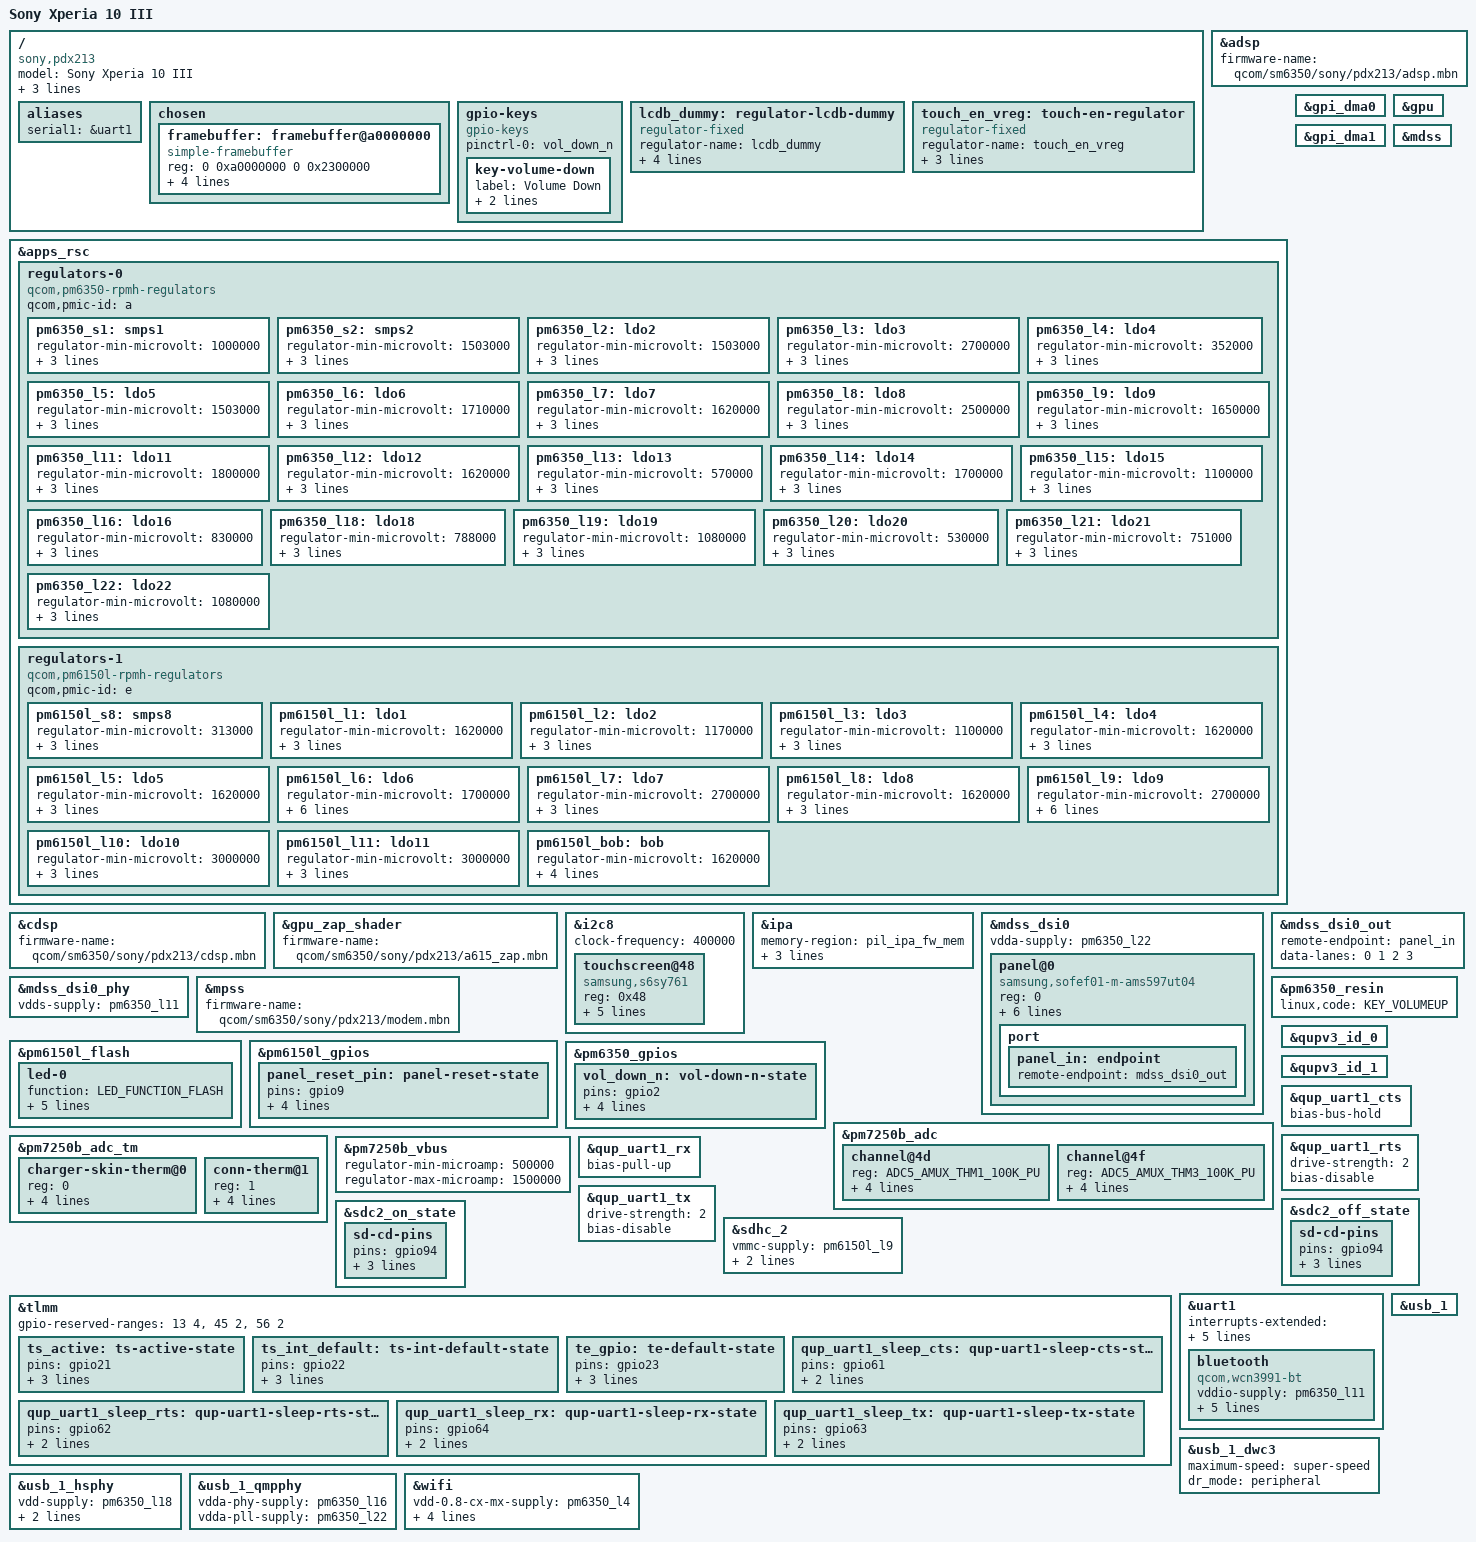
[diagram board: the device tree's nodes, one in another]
// SPDX-License-Identifier: BSD-3-Clause
/*
 * Copyright (c) 2021, Konrad Dybcio <konrad.dybcio@somainline.org>
 */
/dts-v1/;

/* PM7250B is configured to use SID2/3 */
#define PM7250B_SID 2
#define PM7250B_SID1 3

#include <dt-bindings/leds/common.h>
#include <dt-bindings/pinctrl/qcom,pmic-gpio.h>
#include <dt-bindings/regulator/qcom,rpmh-regulator.h>
#include "sm6350.dtsi"
#include "pm6150l.dtsi"
#include "pm6350.dtsi"
#include "pm7250b.dtsi"

/ {
	model = "Sony Xperia 10 III";
	compatible = "sony,pdx213", "qcom,sm6350";
	chassis-type = "handset";
	qcom,msm-id = <434 0x10000>, <459 0x10000>;
	qcom,board-id = <0x1000b 0>;

	aliases {
		serial1 = &uart1;
	};

	chosen {
		#address-cells = <2>;
		#size-cells = <2>;
		ranges;

		framebuffer: framebuffer@a0000000 {
			compatible = "simple-framebuffer";
			reg = <0 0xa0000000 0 0x2300000>;
			width = <1080>;
			height = <2520>;
			stride = <(1080 * 4)>;
			format = "a8r8g8b8";
		};
	};

	gpio-keys {
		compatible = "gpio-keys";
		pinctrl-names = "default";
		pinctrl-0 = <&vol_down_n>;

		key-volume-down {
			label = "Volume Down";
			linux,code = <KEY_VOLUMEDOWN>;
			gpios = <&pm6350_gpios 2 GPIO_ACTIVE_LOW>;
		};
	};

	lcdb_dummy: regulator-lcdb-dummy {
		compatible = "regulator-fixed";
		regulator-name = "lcdb_dummy";
		regulator-min-microvolt = <5500000>;
		regulator-max-microvolt = <5500000>;
		regulator-always-on;
		regulator-boot-on;
	};

	touch_en_vreg: touch-en-regulator {
		compatible = "regulator-fixed";
		regulator-name = "touch_en_vreg";
		gpio = <&tlmm 10 GPIO_ACTIVE_HIGH>;
		enable-active-high;

		vin-supply = <&pm6350_l6>;
	};
};

&adsp {
	firmware-name = "qcom/sm6350/sony/pdx213/adsp.mbn";

	status = "okay";
};

&apps_rsc {
	regulators-0 {
		compatible = "qcom,pm6350-rpmh-regulators";
		qcom,pmic-id = "a";

		pm6350_s1: smps1 {
			regulator-min-microvolt = <1000000>;
			regulator-max-microvolt = <1200000>;
			regulator-initial-mode = <RPMH_REGULATOR_MODE_HPM>;
		};

		pm6350_s2: smps2 {
			regulator-min-microvolt = <1503000>;
			regulator-max-microvolt = <2048000>;
			regulator-initial-mode = <RPMH_REGULATOR_MODE_HPM>;
		};

		pm6350_l2: ldo2 {
			regulator-min-microvolt = <1503000>;
			regulator-max-microvolt = <1980000>;
			regulator-initial-mode = <RPMH_REGULATOR_MODE_HPM>;
		};

		pm6350_l3: ldo3 {
			regulator-min-microvolt = <2700000>;
			regulator-max-microvolt = <3300000>;
			regulator-initial-mode = <RPMH_REGULATOR_MODE_HPM>;
		};

		pm6350_l4: ldo4 {
			regulator-min-microvolt = <352000>;
			regulator-max-microvolt = <801000>;
			regulator-initial-mode = <RPMH_REGULATOR_MODE_HPM>;
		};

		pm6350_l5: ldo5 {
			regulator-min-microvolt = <1503000>;
			regulator-max-microvolt = <1980000>;
			regulator-initial-mode = <RPMH_REGULATOR_MODE_HPM>;
		};

		pm6350_l6: ldo6 {
			regulator-min-microvolt = <1710000>;
			regulator-max-microvolt = <3544000>;
			regulator-initial-mode = <RPMH_REGULATOR_MODE_HPM>;
		};

		pm6350_l7: ldo7 {
			regulator-min-microvolt = <1620000>;
			regulator-max-microvolt = <1980000>;
			regulator-initial-mode = <RPMH_REGULATOR_MODE_HPM>;
		};

		pm6350_l8: ldo8 {
			regulator-min-microvolt = <2500000>;
			regulator-max-microvolt = <3544000>;
			regulator-initial-mode = <RPMH_REGULATOR_MODE_HPM>;
		};

		pm6350_l9: ldo9 {
			regulator-min-microvolt = <1650000>;
			regulator-max-microvolt = <3401000>;
			regulator-initial-mode = <RPMH_REGULATOR_MODE_HPM>;
		};

		pm6350_l11: ldo11 {
			regulator-min-microvolt = <1800000>;
			regulator-max-microvolt = <2000000>;
			regulator-initial-mode = <RPMH_REGULATOR_MODE_HPM>;
		};

		pm6350_l12: ldo12 {
			regulator-min-microvolt = <1620000>;
			regulator-max-microvolt = <1980000>;
			regulator-initial-mode = <RPMH_REGULATOR_MODE_HPM>;
		};

		pm6350_l13: ldo13 {
			regulator-min-microvolt = <570000>;
			regulator-max-microvolt = <650000>;
			regulator-initial-mode = <RPMH_REGULATOR_MODE_HPM>;
		};

		pm6350_l14: ldo14 {
			regulator-min-microvolt = <1700000>;
			regulator-max-microvolt = <1900000>;
			regulator-initial-mode = <RPMH_REGULATOR_MODE_HPM>;
		};

		pm6350_l15: ldo15 {
			regulator-min-microvolt = <1100000>;
			regulator-max-microvolt = <1305000>;
			regulator-initial-mode = <RPMH_REGULATOR_MODE_HPM>;
		};

		pm6350_l16: ldo16 {
			regulator-min-microvolt = <830000>;
			regulator-max-microvolt = <921000>;
			regulator-initial-mode = <RPMH_REGULATOR_MODE_HPM>;
		};

		pm6350_l18: ldo18 {
			regulator-min-microvolt = <788000>;
			regulator-max-microvolt = <1049000>;
			regulator-initial-mode = <RPMH_REGULATOR_MODE_HPM>;
		};

		pm6350_l19: ldo19 {
			regulator-min-microvolt = <1080000>;
			regulator-max-microvolt = <1305000>;
			regulator-initial-mode = <RPMH_REGULATOR_MODE_HPM>;
		};

		pm6350_l20: ldo20 {
			regulator-min-microvolt = <530000>;
			regulator-max-microvolt = <801000>;
			regulator-initial-mode = <RPMH_REGULATOR_MODE_HPM>;
		};

		pm6350_l21: ldo21 {
			regulator-min-microvolt = <751000>;
			regulator-max-microvolt = <825000>;
			regulator-initial-mode = <RPMH_REGULATOR_MODE_HPM>;
		};

		pm6350_l22: ldo22 {
			regulator-min-microvolt = <1080000>;
			regulator-max-microvolt = <1305000>;
			regulator-initial-mode = <RPMH_REGULATOR_MODE_HPM>;
		};
	};

	regulators-1 {
		compatible = "qcom,pm6150l-rpmh-regulators";
		qcom,pmic-id = "e";

		pm6150l_s8: smps8 {
			regulator-min-microvolt = <313000>;
			regulator-max-microvolt = <1395000>;
			regulator-initial-mode = <RPMH_REGULATOR_MODE_HPM>;
		};

		pm6150l_l1: ldo1 {
			regulator-min-microvolt = <1620000>;
			regulator-max-microvolt = <1980000>;
			regulator-initial-mode = <RPMH_REGULATOR_MODE_HPM>;
		};

		pm6150l_l2: ldo2 {
			regulator-min-microvolt = <1170000>;
			regulator-max-microvolt = <1305000>;
			regulator-initial-mode = <RPMH_REGULATOR_MODE_HPM>;
		};

		pm6150l_l3: ldo3 {
			regulator-min-microvolt = <1100000>;
			regulator-max-microvolt = <1299000>;
			regulator-initial-mode = <RPMH_REGULATOR_MODE_HPM>;
		};

		pm6150l_l4: ldo4 {
			regulator-min-microvolt = <1620000>;
			regulator-max-microvolt = <3300000>;
			regulator-initial-mode = <RPMH_REGULATOR_MODE_HPM>;
		};

		pm6150l_l5: ldo5 {
			regulator-min-microvolt = <1620000>;
			regulator-max-microvolt = <3300000>;
			regulator-initial-mode = <RPMH_REGULATOR_MODE_HPM>;
		};

		pm6150l_l6: ldo6 {
			regulator-min-microvolt = <1700000>;
			regulator-max-microvolt = <2950000>;
			regulator-initial-mode = <RPMH_REGULATOR_MODE_HPM>;
			regulator-allow-set-load;
			regulator-allowed-modes = <RPMH_REGULATOR_MODE_LPM
						   RPMH_REGULATOR_MODE_HPM>;
		};

		pm6150l_l7: ldo7 {
			regulator-min-microvolt = <2700000>;
			regulator-max-microvolt = <3544000>;
			regulator-initial-mode = <RPMH_REGULATOR_MODE_HPM>;
		};

		pm6150l_l8: ldo8 {
			regulator-min-microvolt = <1620000>;
			regulator-max-microvolt = <2000000>;
			regulator-initial-mode = <RPMH_REGULATOR_MODE_HPM>;
		};

		pm6150l_l9: ldo9 {
			regulator-min-microvolt = <2700000>;
			regulator-max-microvolt = <2960000>;
			regulator-initial-mode = <RPMH_REGULATOR_MODE_HPM>;
			regulator-allow-set-load;
			regulator-allowed-modes = <RPMH_REGULATOR_MODE_LPM
						   RPMH_REGULATOR_MODE_HPM>;
		};

		pm6150l_l10: ldo10 {
			regulator-min-microvolt = <3000000>;
			regulator-max-microvolt = <3401000>;
			regulator-initial-mode = <RPMH_REGULATOR_MODE_HPM>;
		};

		pm6150l_l11: ldo11 {
			regulator-min-microvolt = <3000000>;
			regulator-max-microvolt = <3401000>;
			regulator-initial-mode = <RPMH_REGULATOR_MODE_HPM>;
		};

		pm6150l_bob: bob {
			regulator-min-microvolt = <1620000>;
			regulator-max-microvolt = <5492000>;
			regulator-initial-mode = <RPMH_REGULATOR_MODE_AUTO>;
			regulator-allow-bypass;
		};
	};
};

&cdsp {
	firmware-name = "qcom/sm6350/sony/pdx213/cdsp.mbn";

	status = "okay";
};

&gpi_dma0 {
	status = "okay";
};

&gpi_dma1 {
	status = "okay";
};

&gpu {
	status = "okay";
};

&gpu_zap_shader {
	firmware-name = "qcom/sm6350/sony/pdx213/a615_zap.mbn";
};

&i2c8 {
	clock-frequency = <400000>;
	status = "okay";

	touchscreen@48 {
		compatible = "samsung,s6sy761";
		reg = <0x48>;
		interrupt-parent = <&tlmm>;
		interrupts = <22 IRQ_TYPE_LEVEL_LOW>;
		vdd-supply = <&pm6350_l11>;
		avdd-supply = <&touch_en_vreg>;

		pinctrl-names = "default";
		pinctrl-0 = <&ts_int_default &ts_active>;
	};
};

&ipa {
	memory-region = <&pil_ipa_fw_mem>;
	firmware-name = "qcom/sm6350/sony/pdx213/ipa_fws.mbn";
	qcom,gsi-loader = "self";

	status = "okay";
};

&mdss {
	status = "okay";
};

&mdss_dsi0 {
	vdda-supply = <&pm6350_l22>;

	status = "okay";

	panel@0 {
		compatible = "samsung,sofef01-m-ams597ut04";
		reg = <0>;

		reset-gpios = <&pm6150l_gpios 9 GPIO_ACTIVE_LOW>;

		vci-supply = <&pm6350_l6>;
		vddio-supply = <&pm6350_l11>;
		vsn-supply = <&lcdb_dummy>;
		vsp-supply = <&lcdb_dummy>;

		pinctrl-0 = <&te_gpio &panel_reset_pin>;
		pinctrl-names = "default";

		port {
			panel_in: endpoint {
				remote-endpoint = <&mdss_dsi0_out>;
			};
		};
	};
};

&mdss_dsi0_out {
	remote-endpoint = <&panel_in>;
	data-lanes = <0 1 2 3>;
};

&mdss_dsi0_phy {
	vdds-supply = <&pm6350_l11>;

	status = "okay";
};

&mpss {
	firmware-name = "qcom/sm6350/sony/pdx213/modem.mbn";

	status = "okay";
};

&pm6150l_flash {
	status = "okay";

	led-0 {
		function = LED_FUNCTION_FLASH;
		color = <LED_COLOR_ID_WHITE>; // guess
		led-sources = <1>;
		led-max-microamp = <180000>;
		flash-max-microamp = <1000000>;
		flash-max-timeout-us = <1280000>;
	};
};

&pm6150l_gpios {
	panel_reset_pin: panel-reset-state {
		pins = "gpio9";
		function = "func1";
		power-source = <1>;
		bias-disable;
		output-low;
	};
};

&pm6350_gpios {
	vol_down_n: vol-down-n-state {
		pins = "gpio2";
		function = PMIC_GPIO_FUNC_NORMAL;
		power-source = <0>;
		bias-disable;
		input-enable;
	};
};

&pm6350_resin {
	linux,code = <KEY_VOLUMEUP>;
	status = "okay";
};

&pm7250b_adc {
	channel@4d {
		reg = <ADC5_AMUX_THM1_100K_PU>;
		qcom,ratiometric;
		qcom,hw-settle-time = <200>;
		qcom,pre-scaling = <1 1>;
		label = "charger_skin_therm";
	};

	channel@4f {
		reg = <ADC5_AMUX_THM3_100K_PU>;
		qcom,ratiometric;
		qcom,hw-settle-time = <200>;
		qcom,pre-scaling = <1 1>;
		label = "conn_therm";
	};
};

&pm7250b_adc_tm {
	status = "okay";

	charger-skin-therm@0 {
		reg = <0>;
		io-channels = <&pm7250b_adc ADC5_AMUX_THM1_100K_PU>;
		qcom,ratiometric;
		qcom,hw-settle-time-us = <200>;
	};

	conn-therm@1 {
		reg = <1>;
		io-channels = <&pm7250b_adc ADC5_AMUX_THM3_100K_PU>;
		qcom,ratiometric;
		qcom,hw-settle-time-us = <200>;
	};
};

&pm7250b_vbus {
	regulator-min-microamp = <500000>;
	regulator-max-microamp = <1500000>;

	status = "okay";
};

&qupv3_id_0 {
	status = "okay";
};

&qupv3_id_1 {
	status = "okay";
};

/* UART1: HS UART for Bluetooth */
&qup_uart1_cts {
	/*
	 * Configure a bias-bus-hold on CTS to lower power
	 * usage when Bluetooth is turned off. Bus hold will
	 * maintain a low power state regardless of whether
	 * the Bluetooth module drives the pin in either
	 * direction or leaves the pin fully unpowered.
	 */
	bias-bus-hold;
};

&qup_uart1_rts {
	/* We'll drive RTS, so no pull */
	drive-strength = <2>;
	bias-disable;
};

&qup_uart1_rx {
	/*
	 * Configure a pull-up on RX. This is needed to avoid
	 * garbage data when the TX pin of the Bluetooth module is
	 * in tri-state (module powered off or not driving the
	 * signal yet).
	 */
	bias-pull-up;
};

&qup_uart1_tx {
	/* We'll drive TX, so no pull */
	drive-strength = <2>;
	bias-disable;
};

&sdc2_off_state {
	sd-cd-pins {
		pins = "gpio94";
		function = "gpio";
		drive-strength = <2>;
		bias-disable;
	};
};

&sdc2_on_state {
	sd-cd-pins {
		pins = "gpio94";
		function = "gpio";
		drive-strength = <2>;
		bias-pull-up;
	};
};

&sdhc_2 {
	status = "okay";

	vmmc-supply = <&pm6150l_l9>;
	vqmmc-supply = <&pm6150l_l6>;

	cd-gpios = <&tlmm 94 GPIO_ACTIVE_HIGH>;
};

&tlmm {
	gpio-reserved-ranges = <13 4>, <45 2>, <56 2>;

	ts_active: ts-active-state {
		pins = "gpio21";
		function = "gpio";
		drive-strength = <8>;
		bias-pull-up;
	};

	ts_int_default: ts-int-default-state {
		pins = "gpio22";
		function = "gpio";
		drive-strength = <2>;
		bias-disable;
	};

	te_gpio: te-default-state {
		pins = "gpio23";
		function = "mdp_vsync";
		drive-strength = <2>;
		bias-pull-down;
	};

	qup_uart1_sleep_cts: qup-uart1-sleep-cts-state {
		pins = "gpio61";
		function = "gpio";
		/*
		 * Configure a bias-bus-hold on CTS to lower power
		 * usage when Bluetooth is turned off. Bus hold will
		 * maintain a low power state regardless of whether
		 * the Bluetooth module drives the pin in either
		 * direction or leaves the pin fully unpowered.
		 */
		bias-bus-hold;
	};

	qup_uart1_sleep_rts: qup-uart1-sleep-rts-state {
		pins = "gpio62";
		function = "gpio";
		/*
		 * Configure pull-down on RTS. As RTS is active low
		 * signal, pull it low to indicate the BT SoC that it
		 * can wakeup the system anytime from suspend state by
		 * pulling RX low (by sending wakeup bytes).
		 */
		bias-pull-down;
	};

	qup_uart1_sleep_rx: qup-uart1-sleep-rx-state {
		pins = "gpio64";
		function = "gpio";
		/*
		 * Configure a pull-up on RX. This is needed to avoid
		 * garbage data when the TX pin of the Bluetooth module
		 * is floating which may cause spurious wakeups.
		 */
		bias-pull-up;
	};

	qup_uart1_sleep_tx: qup-uart1-sleep-tx-state {
		pins = "gpio63";
		function = "gpio";
		/*
		 * Configure pull-up on TX when it isn't actively driven
		 * to prevent BT SoC from receiving garbage during sleep.
		 */
		bias-pull-up;
	};
};

&uart1 {
	/delete-property/ interrupts;
	interrupts-extended = <&intc GIC_SPI 602 IRQ_TYPE_LEVEL_HIGH>,
			     <&tlmm 64 IRQ_TYPE_EDGE_FALLING>;

	pinctrl-names = "default", "sleep";
	pinctrl-1 = <&qup_uart1_sleep_cts>, <&qup_uart1_sleep_rts>, <&qup_uart1_sleep_tx>, <&qup_uart1_sleep_rx>;

	status = "okay";

	bluetooth {
		compatible = "qcom,wcn3991-bt";
		vddio-supply = <&pm6350_l11>;
		vddxo-supply = <&pm6350_l7>;
		vddrf-supply = <&pm6150l_l2>;
		vddch0-supply = <&pm6150l_l10>;
		swctrl-gpios = <&tlmm 69 GPIO_ACTIVE_HIGH>;
		firmware-name = "crnv32u.bin";
	};
};

&usb_1 {
	status = "okay";
};

&usb_1_dwc3 {
	/delete-property/ usb-role-switch;
	maximum-speed = "super-speed";
	dr_mode = "peripheral";
};

&usb_1_hsphy {
	vdd-supply = <&pm6350_l18>;
	vdda-phy-dpdm-supply = <&pm6350_l3>;
	vdda-pll-supply = <&pm6350_l2>;

	status = "okay";
};

&usb_1_qmpphy {
	vdda-phy-supply = <&pm6350_l16>;
	vdda-pll-supply = <&pm6350_l22>;

	status = "okay";
};

&wifi {
	vdd-0.8-cx-mx-supply = <&pm6350_l4>;
	vdd-1.8-xo-supply = <&pm6350_l7>;
	vdd-1.3-rfa-supply = <&pm6150l_l2>;
	vdd-3.3-ch0-supply = <&pm6150l_l10>;
	vdd-3.3-ch1-supply = <&pm6150l_l11>;

	status = "okay";
};
